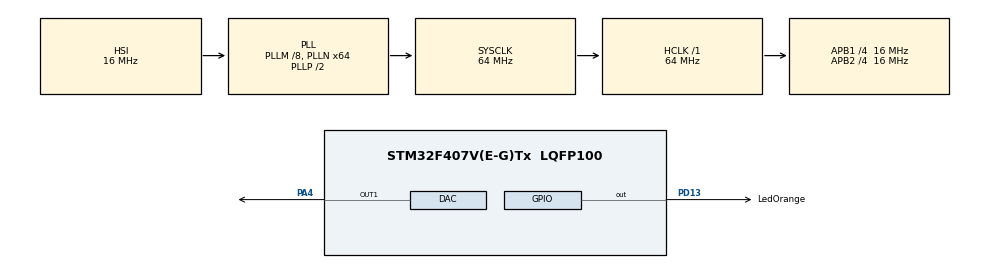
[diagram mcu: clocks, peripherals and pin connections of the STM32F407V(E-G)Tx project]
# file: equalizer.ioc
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DAC.DAC_Trigger=DAC_TRIGGER_T2_TRGO
Dma.DAC1.0.Direction=DMA_MEMORY_TO_PERIPH
Dma.DAC1.0.FIFOMode=DMA_FIFOMODE_DISABLE
Dma.DAC1.0.Instance=DMA1_Stream5
Dma.DAC1.0.MemDataAlignment=DMA_MDATAALIGN_WORD
Dma.DAC1.0.MemInc=DMA_MINC_ENABLE
Dma.DAC1.0.Mode=DMA_CIRCULAR
Dma.DAC1.0.PeriphDataAlignment=DMA_PDATAALIGN_WORD
Dma.DAC1.0.PeriphInc=DMA_PINC_DISABLE
Dma.DAC1.0.Priority=DMA_PRIORITY_LOW
Dma.Request0=DAC1
Mcu.Family=STM32F4
Mcu.Name=STM32F407V(E-G)Tx
Mcu.Package=LQFP100
NVIC.DMA1_Stream5_IRQn=true\:0\:0\:false\:false\:true\:false\:true
NVIC.PriorityGroup=NVIC_PRIORITYGROUP_0
NVIC.TIM2_IRQn=true\:0\:0\:false\:false\:true\:true\:true
PA13.Mode=Serial_Wire
PA13.Signal=SYS_JTMS-SWDIO
PA14.Mode=Serial_Wire
PA14.Signal=SYS_JTCK-SWCLK
PA4.Signal=COMP_DAC1_group
PD13.GPIO_Label=LedOrange
PD13.Signal=GPIO_Output
PH0-OSC_IN.Mode=HSE-External-Oscillator
PH0-OSC_IN.Signal=RCC_OSC_IN
PH1-OSC_OUT.Mode=HSE-External-Oscillator
PH1-OSC_OUT.Signal=RCC_OSC_OUT
ProjectManager.HeapSize=0x200
ProjectManager.StackSize=0x400
ProjectManager.TargetToolchain=STM32CubeIDE
RCC.48MHZClocksFreq_Value=18285714.285714287
RCC.AHBFreq_Value=64000000
RCC.APB1CLKDivider=RCC_HCLK_DIV4
RCC.APB1Freq_Value=16000000
RCC.APB1TimFreq_Value=32000000
RCC.APB2CLKDivider=RCC_HCLK_DIV4
RCC.APB2Freq_Value=16000000
RCC.APB2TimFreq_Value=32000000
RCC.CortexFreq_Value=64000000
RCC.HCLKFreq_Value=64000000
RCC.HSE_VALUE=8000000
RCC.HSI_VALUE=16000000
RCC.LSE_VALUE=32768
RCC.PLLM=8
RCC.PLLN=64
RCC.PLLQ=7
RCC.SYSCLKFreq_VALUE=64000000
RCC.SYSCLKSource=RCC_SYSCLKSOURCE_PLLCLK
RCC.VCOOutputFreq_Value=128000000
SH.COMP_DAC1_group.0=DAC_OUT1,DAC_OUT1
TIM2.Period=10
TIM2.Prescaler=28
TIM2.TIM_MasterOutputTrigger=TIM_TRGO_UPDATE
VP_TIM2_VS_ClockSourceINT.Mode=Internal
board=STM32F407G-DISC1

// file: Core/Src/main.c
/* USER CODE BEGIN Header */
/**
  ******************************************************************************
  * @file           : main.c
  * @brief          : Main program body
  ******************************************************************************
  * @attention
  *
  * <h2><center>&copy; Copyright (c) 2019 STMicroelectronics.
  * All rights reserved.</center></h2>
  *
  * This software component is licensed by ST under Ultimate Liberty license
  * SLA0044, the "License"; You may not use this file except in compliance with
  * the License. You may obtain a copy of the License at:
  *                             www.st.com/SLA0044
  *
  ******************************************************************************
  */
/* USER CODE END Header */

#include "main.h"

DAC_HandleTypeDef hdac;
DMA_HandleTypeDef hdma_dac1;

TIM_HandleTypeDef htim2;

/* USER CODE BEGIN PV */
int LED_State = 0;
int DAC_State = 0;
uint32_t dac_value = 1500;
/* USER CODE END PV */

void SystemClock_Config(void);
static void MX_GPIO_Init(void);
static void MX_DMA_Init(void);
static void MX_DAC_Init(void);
static void MX_TIM2_Init(void);

/* USER CODE BEGIN 0 */

const double samplerate = 100;
double bit12ResMax = 0xFFF;
uint32_t sine_val[100];

 /*
  * Function for getting the sine values for the signal.
  */
void get_sineval ()
{

		for(int i = 0; i < samplerate; i++)
		{
			sine_val[i] = (sin((2*M_PI)*(i/samplerate))+1)*((bit12ResMax)/2);
		}
}

/* USER CODE END 0 */

int main(void)
{
  /* USER CODE BEGIN 1 */
//	double *SineWaveTable;
//	SineWaveTable = sine_wave_gen();

  /* USER CODE END 1 */

  /* MCU Configuration--------------------------------------------------------*/

  /* Reset of all peripherals, Initializes the Flash interface and the Systick. */
  HAL_Init();

  /* Configure the system clock */
  SystemClock_Config();

  /* Initialize all configured peripherals */
  MX_GPIO_Init();
  MX_DMA_Init();
  MX_DAC_Init();
  MX_TIM2_Init();
  /* USER CODE BEGIN 2 */
  HAL_TIM_Base_Start(&htim2);

  get_sineval();

  HAL_DAC_Start_DMA(&hdac, DAC1_CHANNEL_1, sine_val, 100, DAC_ALIGN_12B_R);
  /* USER CODE END 2 */

  /* Infinite loop */
  /* USER CODE BEGIN WHILE */
  while (1)
  {
//	  HAL_Delay(500);
	 // HAL_GPIO_TogglePin(GPIOD, GPIO_PIN_13);
	//  LED_State = HAL_GPIO_ReadPin(GPIOD, GPIO_PIN_13);

//	  HAL_DAC_SetValue(&hdac, DAC_CHANNEL_1, DAC_ALIGN_8B_R, dac_value);
//	  DAC_State = HAL_DAC_GetValue(&hdac, DAC_CHANNEL_1);
//	  HAL_Delay(500);
//	  HAL_DAC_SetValue(&hdac, DAC_CHANNEL_1, DAC_ALIGN_8B_R, 500);
//	  DAC_State = HAL_DAC_GetValue(&hdac, DAC_CHANNEL_1);
//	  HAL_Delay(500);

    /* USER CODE END WHILE */

  }
}

void SystemClock_Config(void)
{
  RCC_OscInitTypeDef RCC_OscInitStruct = {0};
  RCC_ClkInitTypeDef RCC_ClkInitStruct = {0};

  /** Configure the main internal regulator output voltage
  */
  __HAL_RCC_PWR_CLK_ENABLE();
  __HAL_PWR_VOLTAGESCALING_CONFIG(PWR_REGULATOR_VOLTAGE_SCALE1);
  /** Initializes the CPU, AHB and APB busses clocks
  */
  RCC_OscInitStruct.OscillatorType = RCC_OSCILLATORTYPE_HSI;
  RCC_OscInitStruct.HSIState = RCC_HSI_ON;
  RCC_OscInitStruct.HSICalibrationValue = RCC_HSICALIBRATION_DEFAULT;
  RCC_OscInitStruct.PLL.PLLState = RCC_PLL_ON;
  RCC_OscInitStruct.PLL.PLLSource = RCC_PLLSOURCE_HSI;
  RCC_OscInitStruct.PLL.PLLM = 8;
  RCC_OscInitStruct.PLL.PLLN = 64;
  RCC_OscInitStruct.PLL.PLLP = RCC_PLLP_DIV2;
  RCC_OscInitStruct.PLL.PLLQ = 7;
  if (HAL_RCC_OscConfig(&RCC_OscInitStruct) != HAL_OK)
  {
    Error_Handler();
  }
  /** Initializes the CPU, AHB and APB busses clocks
  */
  RCC_ClkInitStruct.ClockType = RCC_CLOCKTYPE_HCLK|RCC_CLOCKTYPE_SYSCLK
                              |RCC_CLOCKTYPE_PCLK1|RCC_CLOCKTYPE_PCLK2;
  RCC_ClkInitStruct.SYSCLKSource = RCC_SYSCLKSOURCE_PLLCLK;
  RCC_ClkInitStruct.AHBCLKDivider = RCC_SYSCLK_DIV1;
  RCC_ClkInitStruct.APB1CLKDivider = RCC_HCLK_DIV4;
  RCC_ClkInitStruct.APB2CLKDivider = RCC_HCLK_DIV4;

  if (HAL_RCC_ClockConfig(&RCC_ClkInitStruct, FLASH_LATENCY_2) != HAL_OK)
  {
    Error_Handler();
  }
}

static void MX_DAC_Init(void)
{

  DAC_ChannelConfTypeDef sConfig = {0};

  /** DAC Initialization
  */
  hdac.Instance = DAC;
  if (HAL_DAC_Init(&hdac) != HAL_OK)
  {
    Error_Handler();
  }
  /** DAC channel OUT1 config
  */
  sConfig.DAC_Trigger = DAC_TRIGGER_T2_TRGO;
  sConfig.DAC_OutputBuffer = DAC_OUTPUTBUFFER_ENABLE;
  if (HAL_DAC_ConfigChannel(&hdac, &sConfig, DAC_CHANNEL_1) != HAL_OK)
  {
    Error_Handler();
  }
  /* USER CODE BEGIN DAC_Init 2 */
//  HAL_DAC_Start(&hdac, DAC_CHANNEL_1);
  /* USER CODE END DAC_Init 2 */

}

static void MX_TIM2_Init(void)
{

  TIM_ClockConfigTypeDef sClockSourceConfig = {0};
  TIM_MasterConfigTypeDef sMasterConfig = {0};

  htim2.Instance = TIM2;
  htim2.Init.Prescaler = 28;
  htim2.Init.CounterMode = TIM_COUNTERMODE_UP;
  htim2.Init.Period = 10;
  htim2.Init.ClockDivision = TIM_CLOCKDIVISION_DIV1;
  htim2.Init.AutoReloadPreload = TIM_AUTORELOAD_PRELOAD_DISABLE;
  if (HAL_TIM_Base_Init(&htim2) != HAL_OK)
  {
    Error_Handler();
  }
  sClockSourceConfig.ClockSource = TIM_CLOCKSOURCE_INTERNAL;
  if (HAL_TIM_ConfigClockSource(&htim2, &sClockSourceConfig) != HAL_OK)
  {
    Error_Handler();
  }
  sMasterConfig.MasterOutputTrigger = TIM_TRGO_UPDATE;
  sMasterConfig.MasterSlaveMode = TIM_MASTERSLAVEMODE_DISABLE;
  if (HAL_TIMEx_MasterConfigSynchronization(&htim2, &sMasterConfig) != HAL_OK)
  {
    Error_Handler();
  }

}

static void MX_DMA_Init(void)
{

  /* DMA controller clock enable */
  __HAL_RCC_DMA1_CLK_ENABLE();

  /* DMA interrupt init */
  /* DMA1_Stream5_IRQn interrupt configuration */
  HAL_NVIC_SetPriority(DMA1_Stream5_IRQn, 0, 0);
  HAL_NVIC_EnableIRQ(DMA1_Stream5_IRQn);

}

static void MX_GPIO_Init(void)
{
  GPIO_InitTypeDef GPIO_InitStruct = {0};

  /* GPIO Ports Clock Enable */
  __HAL_RCC_GPIOH_CLK_ENABLE();
  __HAL_RCC_GPIOA_CLK_ENABLE();
  __HAL_RCC_GPIOD_CLK_ENABLE();

  /*Configure GPIO pin Output Level */
  HAL_GPIO_WritePin(LedOrange_GPIO_Port, LedOrange_Pin, GPIO_PIN_RESET);

  /*Configure GPIO pin : LedOrange_Pin */
  GPIO_InitStruct.Pin = LedOrange_Pin;
  GPIO_InitStruct.Mode = GPIO_MODE_OUTPUT_PP;
  GPIO_InitStruct.Pull = GPIO_NOPULL;
  GPIO_InitStruct.Speed = GPIO_SPEED_FREQ_LOW;
  HAL_GPIO_Init(LedOrange_GPIO_Port, &GPIO_InitStruct);

}

void Error_Handler(void)
{
}

/************************ (C) COPYRIGHT STMicroelectronics *****END OF FILE****/
